# HDSC_HC32F4A0 register map
Vendor: HDSC Co.,Ltd.; Series: ARMCM4; File version: 1.0
CPU: CM4 r0p1, little endian, MPU, FPU, 4 interrupt priority bits
Registers are 32-bit, read-write, reset 0x0 unless marked. A register's access mark holds for its fields unless they carry their own. Offsets are from the block's base; [hi:lo] are bit positions; {n}, {i} and the like mark numbered series; 'fields as' and 'values as' point back to an identical list.

## CMU
Base 0x4004C400
0x00 XTAL32CR 8-bit
  [0] XTAL32STP
0x04 XTAL32CFGR 8-bit
  [2:0] XTAL32DRV
0x14 XTAL32NFR 8-bit
  [1:0] XTAL32NF
0x1C LRCCR 8-bit
  [0] LRCSTP
0x20 RTCLRCCR 8-bit
  [0] RTCLRCSTP
0x24 LRCTRM 8-bit
0x2C RTCLRCTRM 8-bit
0x78 XTALCR 8-bit reset 0x1
  [0] XTALSTP
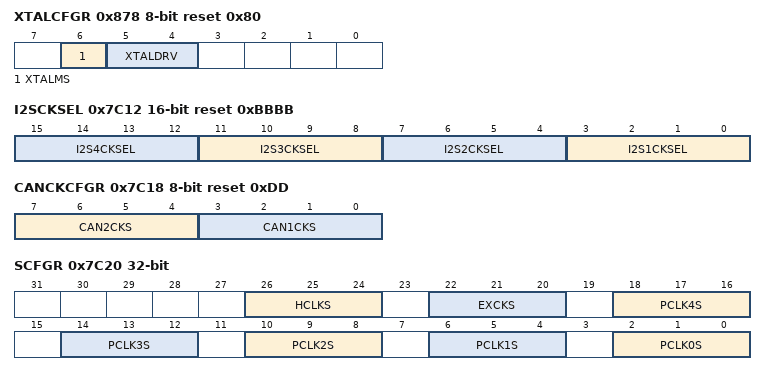
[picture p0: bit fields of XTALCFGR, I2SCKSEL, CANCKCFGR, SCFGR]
0x878 XTALCFGR 8-bit reset 0x80
  [6] XTALMS, [5:4] XTALDRV
0x7C10 PERICKSEL 16-bit
  [3:0] PERICKSEL
0x7C12 I2SCKSEL 16-bit reset 0xBBBB
  [4n-1:4n-4] I2S{n}CKSEL (n=1..4)
0x7C18 CANCKCFGR 8-bit reset 0xDD
  [7:4] CAN2CKS, [3:0] CAN1CKS
0x7C20 SCFGR
  [26:24] HCLKS, [22:20] EXCKS, [4n+2:4n] PCLK{n}S (n=0..4)
0x7C24 USBCKCFGR 8-bit reset 0x40
  [7:4] USBCKS
0x7C26 CKSWR 8-bit reset 0x1
  [2:0] CKSW
0x7C2A PLLHCR 8-bit reset 0x1
  [0] PLLHOFF
0x7C2E PLLACR 8-bit reset 0x1
  [0] PLLAOFF
0x7C36 HRCCR 8-bit reset 0x1
  [0] HRCSTP
0x7C38 MRCCR 8-bit reset 0x80
  [0] MRCSTP
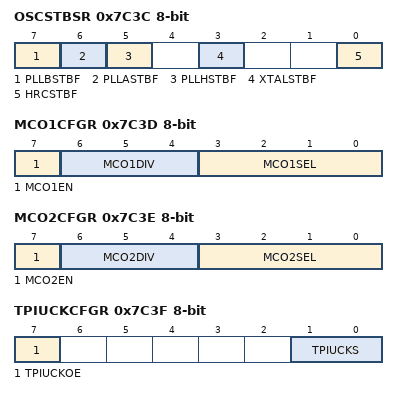
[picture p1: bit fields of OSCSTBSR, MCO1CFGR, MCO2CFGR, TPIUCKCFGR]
0x7C3C OSCSTBSR 8-bit
  [7] PLLBSTBF, [6] PLLASTBF, [5] PLLHSTBF, [3] XTALSTBF, [0] HRCSTBF
0x7C3D MCO1CFGR 8-bit
  [7] MCO1EN, [6:4] MCO1DIV, [3:0] MCO1SEL
0x7C3E MCO2CFGR 8-bit
  [7] MCO2EN, [6:4] MCO2DIV, [3:0] MCO2SEL
0x7C3F TPIUCKCFGR 8-bit
  [7] TPIUCKOE, [1:0] TPIUCKS
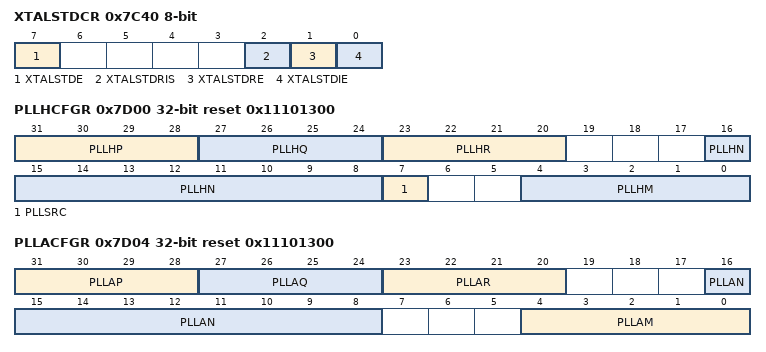
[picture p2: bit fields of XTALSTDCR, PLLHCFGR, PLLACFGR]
0x7C40 XTALSTDCR 8-bit
  [7] XTALSTDE, [2] XTALSTDRIS, [1] XTALSTDRE, [0] XTALSTDIE
0x7C41 XTALSTDSR 8-bit
  [0] XTALSTDF
0x7C61 MRCTRM 8-bit
0x7C62 HRCTRM 8-bit
0x7CA2 XTALSTBCR 8-bit reset 0x5
  [3:0] XTALSTB
0x7D00 PLLHCFGR reset 0x11101300
  [31:28] PLLHP, [27:24] PLLHQ, [23:20] PLLHR, [16:8] PLLHN, [7] PLLSRC, [4:0] PLLHM
0x7D04 PLLACFGR reset 0x11101300
  [31:28] PLLAP, [27:24] PLLAQ, [23:20] PLLAR, [16:8] PLLAN, [4:0] PLLAM

## CRC
Base 0x40008C00
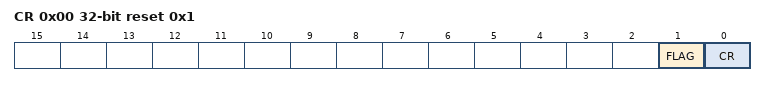
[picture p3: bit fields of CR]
0x00 CR reset 0x1
  [1] FLAG ro, [0] CR
0x04 RESLT
{0x80+4i} DAT{i} ro (i=0..31)

## CTC
Base 0x40049C00
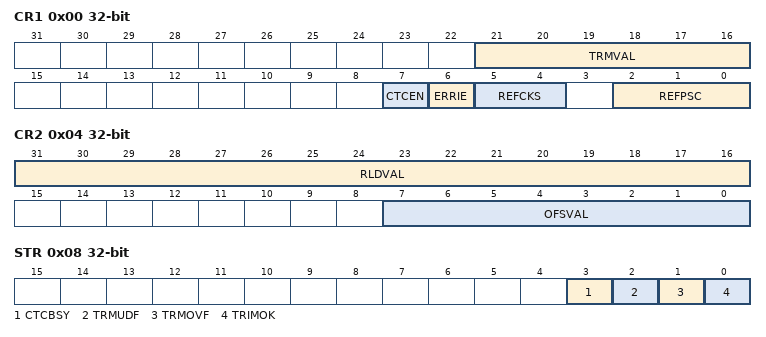
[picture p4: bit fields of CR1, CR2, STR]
0x00 CR1
  [21:16] TRMVAL, [7] CTCEN, [6] ERRIE, [5:4] REFCKS, [2:0] REFPSC
0x04 CR2
  [31:16] RLDVAL, [7:0] OFSVAL
0x08 STR ro
  [3] CTCBSY, [2] TRMUDF, [1] TRMOVF, [0] TRIMOK

## DAC1
Base 0x40041000
Same registers: DAC2 0x40041400
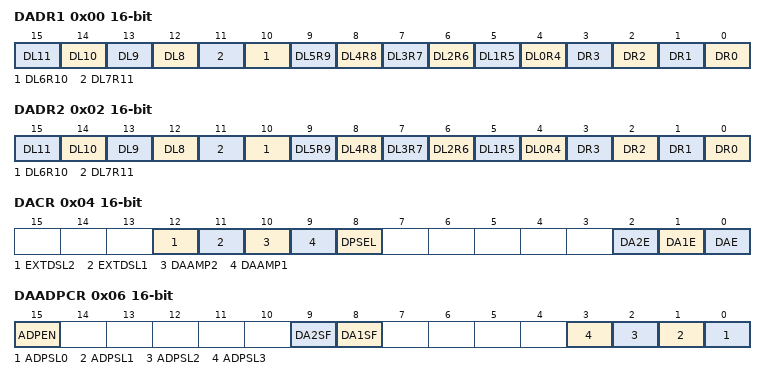
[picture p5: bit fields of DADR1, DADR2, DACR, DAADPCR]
0x00 DADR1 16-bit
  [n+4] DL{n} (n=8..11), [n+4] DL{n}R{n+4} (n=0..7), [n] DR{n} (n=0..3)
0x02 DADR2 16-bit
  fields as DADR1
0x04 DACR 16-bit
  [12] EXTDSL2, [11] EXTDSL1, [10] DAAMP2, [9] DAAMP1, [8] DPSEL, [2] DA2E, [1] DA1E, [0] DAE
0x06 DAADPCR 16-bit
  [15] ADPEN, [9] DA2SF ro, [8] DA1SF ro, [n] ADPSL{n} (n=0..3)
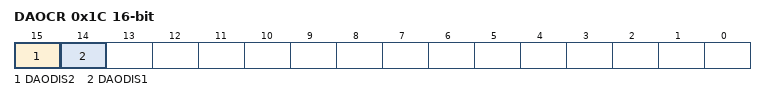
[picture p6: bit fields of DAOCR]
0x1C DAOCR 16-bit
  [15] DAODIS2, [14] DAODIS1

## DBGC
Base 0xE0042000
{0x0+4i} AUTHID{i} (i=0..2)
0x0C RESV0
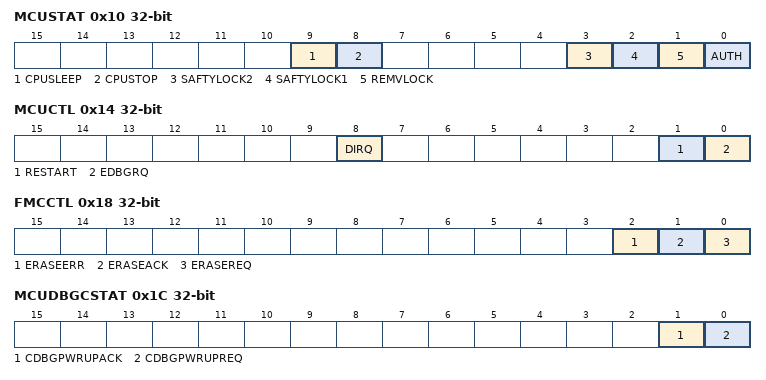
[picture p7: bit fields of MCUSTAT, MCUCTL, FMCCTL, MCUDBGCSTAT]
0x10 MCUSTAT
  [9] CPUSLEEP, [8] CPUSTOP, [3] SAFTYLOCK2, [2] SAFTYLOCK1, [1] REMVLOCK, [0] AUTH
0x14 MCUCTL
  [8] DIRQ, [1] RESTART, [0] EDBGRQ
0x18 FMCCTL
  [2] ERASEERR, [1] ERASEACK, [0] ERASEREQ
0x1C MCUDBGCSTAT
  [1] CDBGPWRUPACK, [0] CDBGPWRUPREQ
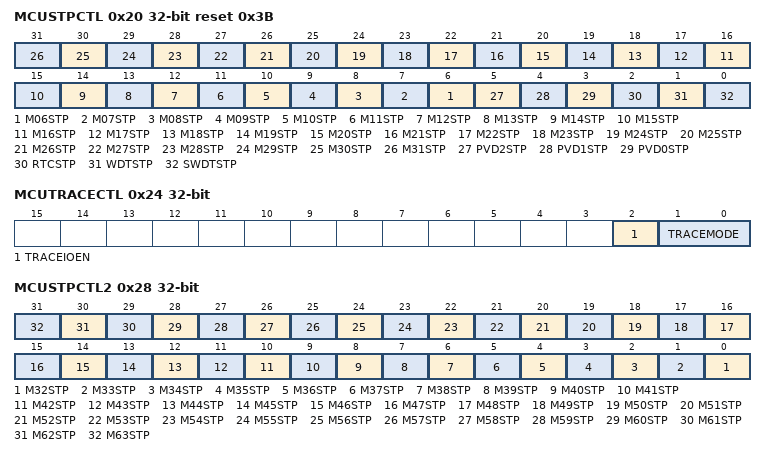
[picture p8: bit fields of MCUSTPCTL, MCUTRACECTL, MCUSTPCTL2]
0x20 MCUSTPCTL reset 0x3B
  [n] M{n:02}STP (n=6..31), [5] PVD2STP, [4] PVD1STP, [3] PVD0STP, [2] RTCSTP, [1] WDTSTP, [0] SWDTSTP
0x24 MCUTRACECTL
  [2] TRACEIOEN, [1:0] TRACEMODE
0x28 MCUSTPCTL2
  [n-32] M{n}STP (n=32..63)

## DCU1
Base 0x40056000
Same registers: DCU2 0x40056400, DCU3 0x40056800, DCU4 0x40056C00, DCU5 0x40057000, DCU6 0x40057400, DCU7 0x40057800, DCU8 0x40057C00
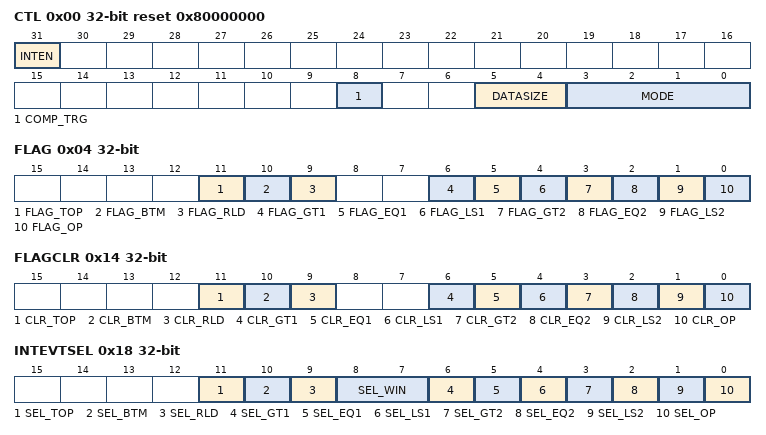
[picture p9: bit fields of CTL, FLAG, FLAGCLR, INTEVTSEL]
0x00 CTL reset 0x80000000
  [31] INTEN, [8] COMP_TRG, [5:4] DATASIZE, [3:0] MODE
0x04 FLAG ro
  [11] FLAG_TOP, [10] FLAG_BTM, [9] FLAG_RLD, [6] FLAG_GT1, [5] FLAG_EQ1, [4] FLAG_LS1, [3] FLAG_GT2, [2] FLAG_EQ2, [1] FLAG_LS2, [0] FLAG_OP
{0x8+4i} DATA{i} (i=0..2)
0x14 FLAGCLR wo
  [11] CLR_TOP rw, [10] CLR_BTM rw, [9] CLR_RLD rw, [6] CLR_GT1, [5] CLR_EQ1, [4] CLR_LS1, [3] CLR_GT2, [2] CLR_EQ2, [1] CLR_LS2, [0] CLR_OP
0x18 INTEVTSEL
  [11] SEL_TOP, [10] SEL_BTM, [9] SEL_RLD, [8:7] SEL_WIN, [6] SEL_GT1, [5] SEL_EQ1, [4] SEL_LS1, [3] SEL_GT2, [2] SEL_EQ2, [1] SEL_LS2, [0] SEL_OP
